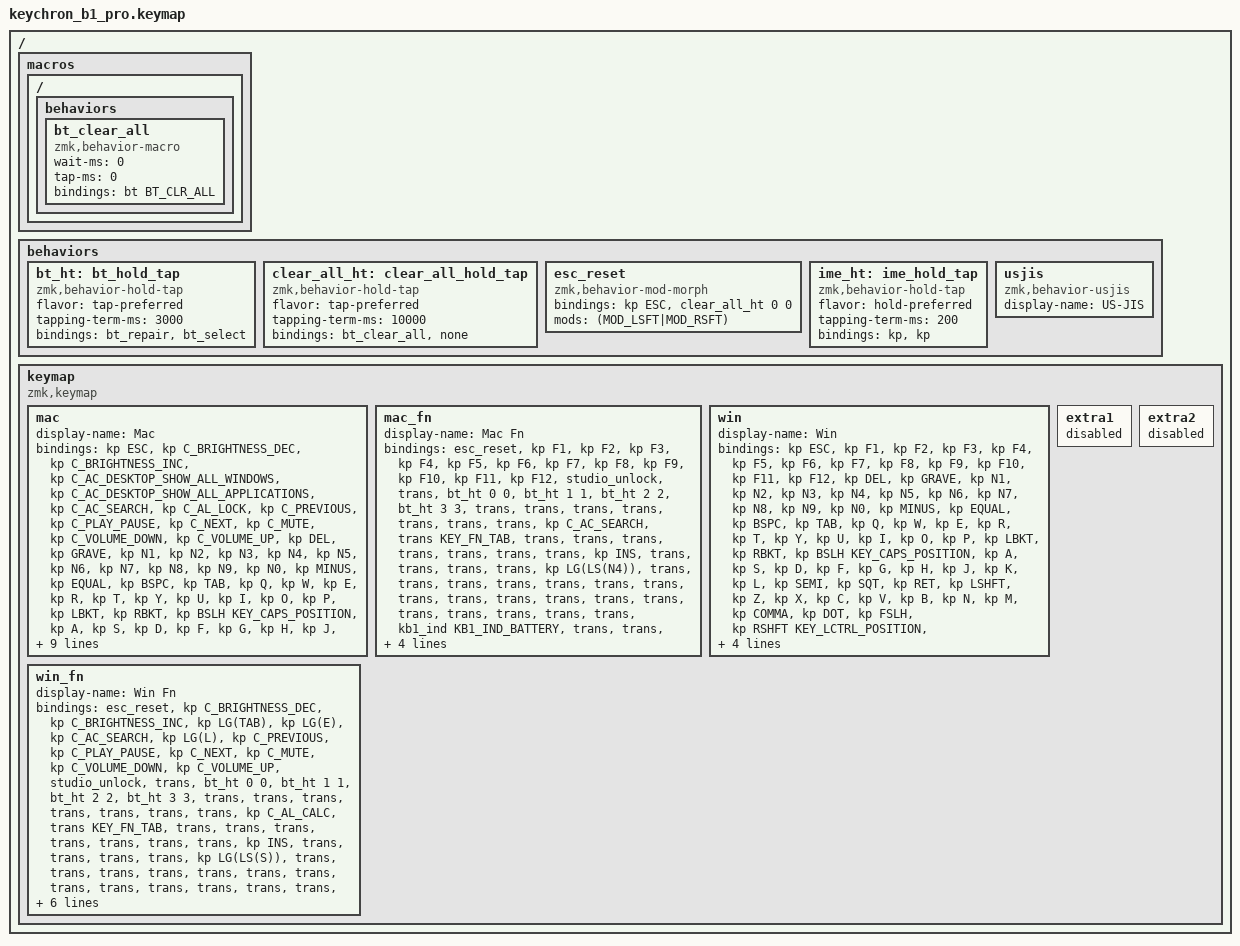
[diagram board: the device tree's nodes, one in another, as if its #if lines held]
/*
 * Copyright (c) 2026 zmk-kb1 contributors
 *
 * SPDX-License-Identifier: MIT
 *
 * Keymap of the Keychron B1 Pro US on upstream ZMK.
 *
 * Layers: 0 Mac, 1 Mac Fn, 2 Win, 3 Win Fn. The Mac/Win switch holds layer 2
 * (&mo 2) in the Win position. The last row of each layer is the five direct
 * inputs: Mac/Win, the BT and 2.4G positions of the connection switch, and the
 * charger's charging and charge-done signals; only layer 0 binds them. The
 * connection switch: BT = Bluetooth, cable = USB, 2.4G = off (soft off; the
 * keyboard wakes when the switch leaves 2.4G).
 *
 * Fn layer: Fn+1..4 select a Bluetooth profile (hold 3 s: forget it and pair
 * anew), Fn+Shift+Esc held 10 s clears all Bluetooth bonds, Fn+Tab toggles
 * US-JIS substitution (applied in the Win position only; with B1_USJIS),
 * Fn+B shows the battery level on the RGB LED while held, Fn+Del unlocks ZMK
 * Studio. The options are in keymap-options.h.
 */

#include <behaviors.dtsi>

/* ZMK's &soft_off would turn the keyboard off without turning the LEDs off
 * first (they would stay lit through System OFF); the connection switch and
 * src/kb1_power.c turn it off instead. Removed so that ZMK Studio cannot
 * assign it. */
/delete-node/ &soft_off;
#include <dt-bindings/zmk/keys.h>
#include <dt-bindings/zmk/bt.h>
#include <dt-bindings/zmk/outputs.h>
#include <dt-bindings/kb1/conn_switch.h>
#include <dt-bindings/kb1/indicator.h>
#include "keymap-options.h"

#if B1_USJIS
#include <dt-bindings/zmk/usjis.h>
#define KEY_FN_TAB &usjis USJIS_TOG
#else
#define KEY_FN_TAB &trans
#endif

#if B1_IME_TAP
#define KEY_L_OF_SPACE_MAC &ime_ht LCMD LANG2
#define KEY_R_OF_SPACE_MAC &ime_ht RCMD LANG1
#define KEY_L_OF_SPACE_WIN &ime_ht LALT INT5
#define KEY_R_OF_SPACE_WIN &ime_ht RALT INT4
#else
#define KEY_L_OF_SPACE_MAC &kp LCMD
#define KEY_R_OF_SPACE_MAC &kp RCMD
#define KEY_L_OF_SPACE_WIN &kp LALT
#define KEY_R_OF_SPACE_WIN &kp RALT
#endif

#if B1_SWAP_CTRL_CAPS
#define KEY_CAPS_POSITION &kp LCTRL
#define KEY_LCTRL_POSITION &kp CLCK
#else
#define KEY_CAPS_POSITION &kp CLCK
#define KEY_LCTRL_POSITION &kp LCTRL
#endif

/ {
    macros {
        // Select Bluetooth profile N (one parameter, for the hold-tap below).
        ZMK_MACRO1(bt_select,
            wait-ms = <0>;
            tap-ms = <0>;
            bindings = <&macro_param_1to2 &bt BT_SEL MACRO_PLACEHOLDER>;
        )
        // Select profile N and forget its bond, so that it pairs anew.
        ZMK_MACRO1(bt_repair,
            wait-ms = <0>;
            tap-ms = <0>;
            bindings = <&macro_param_1to2 &bt BT_SEL MACRO_PLACEHOLDER>, <&bt BT_CLR>;
        )
        ZMK_MACRO(bt_clear_all,
            wait-ms = <0>;
            tap-ms = <0>;
            bindings = <&bt BT_CLR_ALL>;
        )
    };

    behaviors {
        // Fn+1..4: tap selects the profile, a 3 s hold pairs it anew.
        bt_ht: bt_hold_tap {
            compatible = "zmk,behavior-hold-tap";
            #binding-cells = <2>;
            flavor = "tap-preferred";
            tapping-term-ms = <3000>;
            bindings = <&bt_repair>, <&bt_select>;
        };

        // A 10 s hold clears all Bluetooth bonds; a shorter press does nothing.
        clear_all_ht: clear_all_hold_tap {
            compatible = "zmk,behavior-hold-tap";
            #binding-cells = <2>;
            flavor = "tap-preferred";
            tapping-term-ms = <10000>;
            bindings = <&bt_clear_all>, <&none>;
        };

        // Fn+Esc: Esc. Fn+Shift+Esc: clear all bonds after a 10 s hold.
        esc_reset: esc_reset {
            compatible = "zmk,behavior-mod-morph";
            #binding-cells = <0>;
            bindings = <&kp ESC>, <&clear_all_ht 0 0>;
            mods = <(MOD_LSFT|MOD_RSFT)>;
        };

#if B1_IME_TAP
        // Modifier when held, IME key when tapped (the keys beside Space).
        // hold-preferred: any key pressed while it is held makes it the
        // modifier, so Alt/Cmd shortcuts are not delayed.
        ime_ht: ime_hold_tap {
            compatible = "zmk,behavior-hold-tap";
            #binding-cells = <2>;
            flavor = "hold-preferred";
            tapping-term-ms = <200>;
            bindings = <&kp>, <&kp>;
        };
#endif

#if B1_USJIS
        // US-JIS substitution mode (src/usjis.c, docs/usjis-substitution.md).
        usjis: usjis {
            compatible = "zmk,behavior-usjis";
            #binding-cells = <1>;
            display-name = "US-JIS";
        };
#endif
    };

    keymap {
        compatible = "zmk,keymap";

        mac {
            display-name = "Mac";
            bindings = <
&kp ESC            &kp C_BRIGHTNESS_DEC &kp C_BRIGHTNESS_INC &kp C_AC_DESKTOP_SHOW_ALL_WINDOWS &kp C_AC_DESKTOP_SHOW_ALL_APPLICATIONS &kp C_AC_SEARCH &kp C_AL_LOCK &kp C_PREVIOUS &kp C_PLAY_PAUSE &kp C_NEXT &kp C_MUTE &kp C_VOLUME_DOWN &kp C_VOLUME_UP &kp DEL
&kp GRAVE          &kp N1   &kp N2   &kp N3   &kp N4   &kp N5   &kp N6   &kp N7   &kp N8    &kp N9  &kp N0   &kp MINUS &kp EQUAL &kp BSPC
&kp TAB            &kp Q    &kp W    &kp E    &kp R    &kp T    &kp Y    &kp U    &kp I     &kp O   &kp P    &kp LBKT  &kp RBKT  &kp BSLH
KEY_CAPS_POSITION  &kp A    &kp S    &kp D    &kp F    &kp G    &kp H    &kp J    &kp K     &kp L   &kp SEMI &kp SQT             &kp RET
&kp LSHFT                   &kp Z    &kp X    &kp C    &kp V    &kp B    &kp N    &kp M     &kp COMMA &kp DOT &kp FSLH           &kp RSHFT
KEY_LCTRL_POSITION &kp LALT KEY_L_OF_SPACE_MAC  &kp SPACE  KEY_R_OF_SPACE_MAC &mo 1 &kp LEFT &kp UP &kp DOWN &kp RIGHT
&mo 2              &conn_sw CONN_SW_BT &conn_sw CONN_SW_OFF &none &none
            >;
        };

        mac_fn {
            display-name = "Mac Fn";
            bindings = <
&esc_reset         &kp F1   &kp F2   &kp F3   &kp F4   &kp F5   &kp F6   &kp F7   &kp F8    &kp F9  &kp F10  &kp F11   &kp F12   &studio_unlock
&trans             &bt_ht 0 0 &bt_ht 1 1 &bt_ht 2 2 &bt_ht 3 3 &trans &trans &trans &trans &trans &trans &trans &kp C_AC_SEARCH &trans
KEY_FN_TAB         &trans   &trans   &trans   &trans   &trans   &trans   &trans   &kp INS   &trans  &trans   &trans    &trans    &kp LG(LS(N4))
&trans             &trans   &trans   &trans   &trans   &trans   &trans   &trans   &trans    &trans  &trans   &trans              &trans
&trans                      &trans   &trans   &trans   &trans   &kb1_ind KB1_IND_BATTERY &trans &trans &trans &trans &trans &kp LC(LG(SPACE))
&trans             &trans   &trans   &trans   &kp RCTRL &trans &kp HOME &kp PG_UP &kp PG_DN &kp END
&trans             &trans   &trans   &trans   &trans
            >;
        };

        win {
            display-name = "Win";
            bindings = <
&kp ESC            &kp F1   &kp F2   &kp F3   &kp F4   &kp F5   &kp F6   &kp F7   &kp F8    &kp F9  &kp F10  &kp F11   &kp F12   &kp DEL
&kp GRAVE          &kp N1   &kp N2   &kp N3   &kp N4   &kp N5   &kp N6   &kp N7   &kp N8    &kp N9  &kp N0   &kp MINUS &kp EQUAL &kp BSPC
&kp TAB            &kp Q    &kp W    &kp E    &kp R    &kp T    &kp Y    &kp U    &kp I     &kp O   &kp P    &kp LBKT  &kp RBKT  &kp BSLH
KEY_CAPS_POSITION  &kp A    &kp S    &kp D    &kp F    &kp G    &kp H    &kp J    &kp K     &kp L   &kp SEMI &kp SQT             &kp RET
&kp LSHFT                   &kp Z    &kp X    &kp C    &kp V    &kp B    &kp N    &kp M     &kp COMMA &kp DOT &kp FSLH           &kp RSHFT
KEY_LCTRL_POSITION &kp LGUI KEY_L_OF_SPACE_WIN  &kp SPACE  KEY_R_OF_SPACE_WIN &mo 3 &kp LEFT &kp UP &kp DOWN &kp RIGHT
&trans             &trans   &trans   &trans   &trans
            >;
        };

        win_fn {
            display-name = "Win Fn";
            bindings = <
&esc_reset         &kp C_BRIGHTNESS_DEC &kp C_BRIGHTNESS_INC &kp LG(TAB) &kp LG(E) &kp C_AC_SEARCH &kp LG(L) &kp C_PREVIOUS &kp C_PLAY_PAUSE &kp C_NEXT &kp C_MUTE &kp C_VOLUME_DOWN &kp C_VOLUME_UP &studio_unlock
&trans             &bt_ht 0 0 &bt_ht 1 1 &bt_ht 2 2 &bt_ht 3 3 &trans &trans &trans &trans &trans &trans &trans &kp C_AL_CALC &trans
KEY_FN_TAB         &trans   &trans   &trans   &trans   &trans   &trans   &trans   &kp INS   &trans  &trans   &trans    &trans    &kp LG(LS(S))
&trans             &trans   &trans   &trans   &trans   &trans   &trans   &trans   &trans    &trans  &trans   &trans              &trans
&trans                      &trans   &trans   &trans   &trans   &kb1_ind KB1_IND_BATTERY &trans &trans &trans &trans &trans &kp LG(DOT)
&trans             &trans   &trans   &trans   &kp RCTRL &trans &kp HOME &kp PG_UP &kp PG_DN &kp END
&trans             &trans   &trans   &trans   &trans
            >;
        };

        // Spare layers that ZMK Studio can enable and fill in.
        extra1 {
            status = "reserved";
        };
        extra2 {
            status = "reserved";
        };
    };
};
